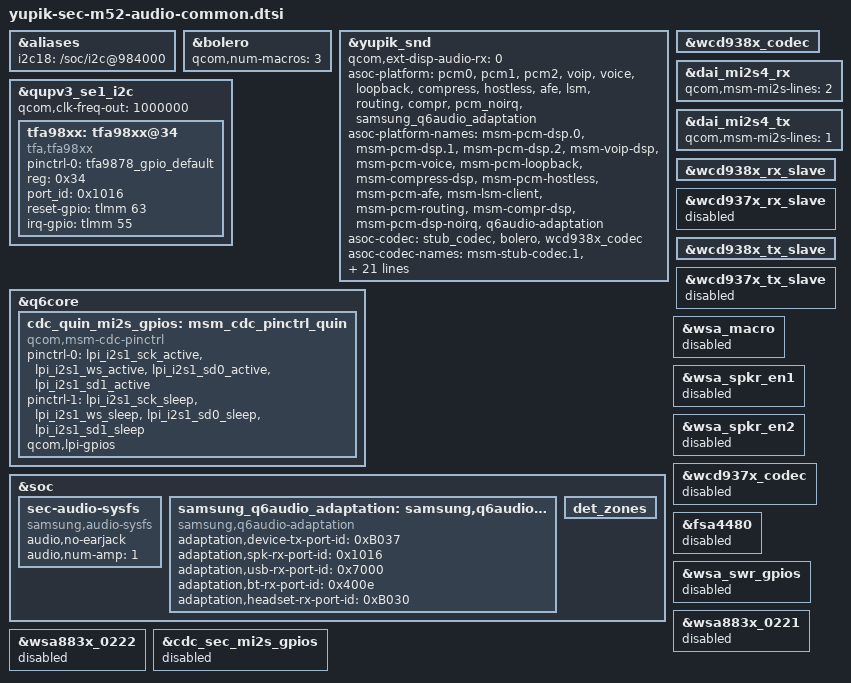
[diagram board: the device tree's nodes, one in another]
/* Copyright (c) 2019, The Linux Foundation. All rights reserved.
 *
 * This program is free software; you can redistribute it and/or modify
 * it under the terms of the GNU General Public License version 2 and
 * only version 2 as published by the Free Software Foundation.
 *
 * This program is distributed in the hope that it will be useful,
 * but WITHOUT ANY WARRANTY; without even the implied warranty of
 * MERCHANTABILITY or FITNESS FOR A PARTICULAR PURPOSE.  See the
 * GNU General Public License for more details.
 */

&aliases {
	i2c18 = "/soc/i2c@984000";
};

&bolero {
	qcom,num-macros = <3>;
};

&yupik_snd {
	qcom,ext-disp-audio-rx = <0>;

	asoc-platform = <&pcm0>, <&pcm1>, <&pcm2>, <&voip>, <&voice>,
			<&loopback>, <&compress>, <&hostless>,
			<&afe>, <&lsm>, <&routing>, <&compr>,
			<&pcm_noirq>, <&samsung_q6audio_adaptation>;
	asoc-platform-names = "msm-pcm-dsp.0", "msm-pcm-dsp.1",
			"msm-pcm-dsp.2", "msm-voip-dsp",
			"msm-pcm-voice", "msm-pcm-loopback",
			"msm-compress-dsp", "msm-pcm-hostless",
			"msm-pcm-afe", "msm-lsm-client",
			"msm-pcm-routing", "msm-compr-dsp",
			"msm-pcm-dsp-noirq", "q6audio-adaptation";
	asoc-codec  = <&stub_codec>, <&bolero>,
		      <&wcd938x_codec>;
	asoc-codec-names = "msm-stub-codec.1", "bolero_codec",
			   "wcd938x_codec";
	qcom,audio-routing =
		"AMIC1", "Analog Mic1",
		"Analog Mic1", "MIC BIAS1",
		"AMIC2", "Analog Mic2",
		"Analog Mic2", "MIC BIAS2",
		"AMIC3", "Analog Mic3",
		"Analog Mic3", "MIC BIAS1",
		"AMIC4", "Analog Mic4",
		"Analog Mic4", "MIC BIAS3",
		"IN1_HPHL", "HPHL_OUT",
		"IN2_HPHR", "HPHR_OUT",
		"RX_TX DEC0_INP", "TX DEC0 MUX",
		"RX_TX DEC1_INP", "TX DEC1 MUX",
		"RX_TX DEC2_INP", "TX DEC2 MUX",
		"RX_TX DEC3_INP", "TX DEC3 MUX",
		"TX SWR_INPUT", "WCD_TX_OUTPUT",
		"VA SWR_INPUT", "VA_SWR_CLK",
		"VA SWR_INPUT", "WCD_TX_OUTPUT",
		"VA_AIF1 CAP", "VA_SWR_CLK",
		"VA_AIF2 CAP", "VA_SWR_CLK",
		"VA_AIF3 CAP", "VA_SWR_CLK";

	qcom,cdc-dmic01-gpios = <>;
	qcom,cdc-dmic23-gpios = <>;
	qcom,cdc-dmic45-gpios = <>;
	qcom,sec-mi2s-gpios = <>;
	qcom,quin-mi2s-gpios = <&cdc_quin_mi2s_gpios>;
	qcom,wsa-max-devs = <0>;
	fsa4480-i2c-handle = <>;
};

&qupv3_se1_i2c {
	qcom,clk-freq-out = <1000000>;
	status = "ok";

	tfa98xx: tfa98xx@34 {
		compatible = "tfa,tfa98xx";
		pinctrl-names = "default";
		pinctrl-0 = <&tfa9878_gpio_default>;
		reg = <0x34>;
		port_id=<0x1016>;
		reset-gpio = <&tlmm 63 0>;
		irq-gpio = <&tlmm 55 0>;
	};
};

&wcd938x_codec {
	status = "ok";
};

&q6core {
	cdc_quin_mi2s_gpios: msm_cdc_pinctrl_quin {
		compatible = "qcom,msm-cdc-pinctrl";
		pinctrl-names = "aud_active", "aud_sleep";
		pinctrl-0 = <&lpi_i2s1_sck_active &lpi_i2s1_ws_active
				 &lpi_i2s1_sd0_active &lpi_i2s1_sd1_active>;
		pinctrl-1 = <&lpi_i2s1_sck_sleep &lpi_i2s1_ws_sleep
				 &lpi_i2s1_sd0_sleep &lpi_i2s1_sd1_sleep>;
		qcom,lpi-gpios;
		#gpio-cells = <0>;
	};
};

&soc {
	sec-audio-sysfs {
		compatible = "samsung,audio-sysfs";
		status = "okay";
		audio,no-earjack;
		audio,num-amp = <1>;
	};

	samsung_q6audio_adaptation: samsung,q6audio-adaptation {
		compatible = "samsung,q6audio-adaptation";
		adaptation,device-tx-port-id = <0xB037>;
		adaptation,spk-rx-port-id = <0x1016>;
		adaptation,usb-rx-port-id = <0x7000>;
		adaptation,bt-rx-port-id = <0x400e>;
		adaptation,headset-rx-port-id = <0xB030>;
	};

	det_zones: det_zones {
		#list-det-cells = <2>;
	};
};
&dai_mi2s4_rx {
	qcom,msm-mi2s-lines = <2>;
};

&dai_mi2s4_tx {
	qcom,msm-mi2s-lines = <1>;
};

&wcd938x_rx_slave {
	status = "okay";
};

&wcd937x_rx_slave {
	status = "disabled";
};

&wcd938x_tx_slave {
	status = "okay";
};

&wcd937x_tx_slave {
	status = "disabled";
};

&wsa_macro {
	status = "disabled";
};

&wsa_spkr_en1 {
	status = "disabled";
};

&wsa_spkr_en2 {
	status = "disabled";
};

&wcd937x_codec {
	status = "disabled";
};

&fsa4480 {
	status = "disabled";
};

&wsa_swr_gpios {
	status = "disabled";
};

&wsa883x_0221 {
	status = "disabled";
};

&wsa883x_0222 {
	status = "disabled";
};

&cdc_sec_mi2s_gpios {
	status = "disabled";
};
